AUTOSAR XML (schema 4-2-2)
package /STELLANTIS/EPT/ASWCs
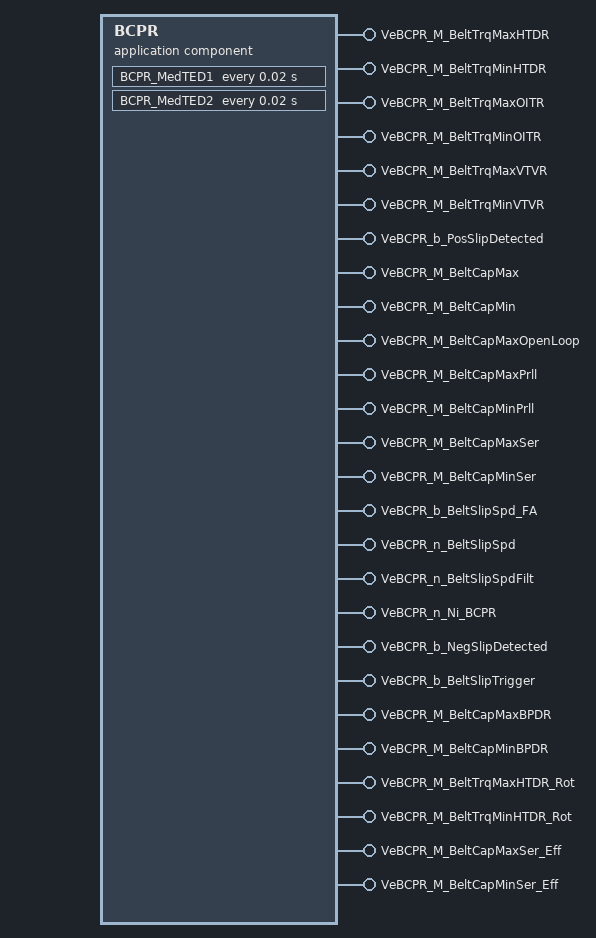
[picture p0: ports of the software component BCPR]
  application sw component type BCPR
    26 x provide port, all with nonqueued-sender-com-spec{data-element=Value, init-value=0}:
      VeBCPR_M_BeltTrqMaxHTDR: provided-interface=VeBCPR_M_BeltTrqMaxHTDR
      VeBCPR_M_BeltTrqMinHTDR: provided-interface=VeBCPR_M_BeltTrqMinHTDR
      VeBCPR_M_BeltTrqMaxOITR: provided-interface=VeBCPR_M_BeltTrqMaxOITR
      VeBCPR_M_BeltTrqMinOITR: provided-interface=VeBCPR_M_BeltTrqMinOITR
      VeBCPR_M_BeltTrqMaxVTVR: provided-interface=VeBCPR_M_BeltTrqMaxVTVR
      VeBCPR_M_BeltTrqMinVTVR: provided-interface=VeBCPR_M_BeltTrqMinVTVR
      VeBCPR_b_PosSlipDetected: provided-interface=VeBCPR_b_PosSlipDetected
      VeBCPR_M_BeltCapMax: provided-interface=VeBCPR_M_BeltCapMax
      VeBCPR_M_BeltCapMin: provided-interface=VeBCPR_M_BeltCapMin
      VeBCPR_M_BeltCapMaxOpenLoop: provided-interface=VeBCPR_M_BeltCapMaxOpenLoop
      VeBCPR_M_BeltCapMaxPrll: provided-interface=VeBCPR_M_BeltCapMaxPrll
      VeBCPR_M_BeltCapMinPrll: provided-interface=VeBCPR_M_BeltCapMinPrll
      VeBCPR_M_BeltCapMaxSer: provided-interface=VeBCPR_M_BeltCapMaxSer
      VeBCPR_M_BeltCapMinSer: provided-interface=VeBCPR_M_BeltCapMinSer
      VeBCPR_b_BeltSlipSpd_FA: provided-interface=VeBCPR_b_BeltSlipSpd_FA
      VeBCPR_n_BeltSlipSpd: provided-interface=VeBCPR_n_BeltSlipSpd
      VeBCPR_n_BeltSlipSpdFilt: provided-interface=VeBCPR_n_BeltSlipSpdFilt
      VeBCPR_n_Ni_BCPR: provided-interface=VeBCPR_n_Ni_BCPR
      VeBCPR_b_NegSlipDetected: provided-interface=VeBCPR_b_NegSlipDetected
      VeBCPR_b_BeltSlipTrigger: provided-interface=VeBCPR_b_BeltSlipTrigger
      VeBCPR_M_BeltCapMaxBPDR: provided-interface=VeBCPR_M_BeltCapMaxBPDR
      VeBCPR_M_BeltCapMinBPDR: provided-interface=VeBCPR_M_BeltCapMinBPDR
      VeBCPR_M_BeltTrqMaxHTDR_Rot: provided-interface=VeBCPR_M_BeltTrqMaxHTDR_Rot
      VeBCPR_M_BeltTrqMinHTDR_Rot: provided-interface=VeBCPR_M_BeltTrqMinHTDR_Rot
      VeBCPR_M_BeltCapMaxSer_Eff: provided-interface=VeBCPR_M_BeltCapMaxSer_Eff
      VeBCPR_M_BeltCapMinSer_Eff: provided-interface=VeBCPR_M_BeltCapMinSer_Eff
    behavior IB_BCPR: data-type-mapping=msADTtoIDTMapping, handle-termination-and-restart=NO-SUPPORT
      timing event Event_MedTED1: start-on-event=BCPR_MedTED1, period=0.02
      timing event Event_MedTED2: start-on-event=BCPR_MedTED2, period=0.02
      init event Event_BCPR_ac_Init: start-on-event=BCPR_ac_Init
      init event Event_PwrOn: start-on-event=BCPR_PwrOn
      explicit-inter-runnable-variables:
        12 x data, all with category=VALUE, sw-calibration-access=READ-ONLY, init-value=0:
          VeBCPC_M_BeltCapMaxOpenLoopTact_write_IRV: type=Float
          VeBCPC_M_BeltCapMinOpenLoopTact_write_IRV: type=Float
          VeBCPC_M_BeltCapMaxOpenLoopPrll_write_IRV: type=Float
          VeBCPC_M_BeltCapMinOpenLoopPrll_write_IRV: type=Float
          VeBCPC_M_BeltCapMaxOpenLoopSer_write_IRV: type=Float
          VeBCPC_M_BeltCapMinOpenLoopSer_write_IRV: type=Float
          VeBCPC_M_BeltCapMaxOpenLoopPred_write_IRV: type=Float
          VeBCPC_M_BeltCapMinOpenLoopPred_write_IRV: type=Float
          PrllRngEqn_write_IRV: type=Boolean
          PrllPreLeadState_write_IRV: type=Boolean
          VeBCPR_n_BeltSlipSpd_write_IRV: type=Float
          VeBCPR_n_BeltSlipSpdFilt_write_IRV: type=Float
      4 x runnable:
        BCPR_ac_Init
        BCPR_PwrOn
          data-send-points:
            26 x access:
              OUT_VeBCPR_M_BeltTrqMaxHTDR_Rot_Value: accessed-variable=VeBCPR_M_BeltTrqMaxHTDR_Rot.Value
              OUT_VeBCPR_M_BeltCapMaxOpenLoop_Value: accessed-variable=VeBCPR_M_BeltCapMaxOpenLoop.Value
              OUT_VeBCPR_M_BeltCapMaxPrll_Value: accessed-variable=VeBCPR_M_BeltCapMaxPrll.Value
              OUT_VeBCPR_M_BeltCapMinPrll_Value: accessed-variable=VeBCPR_M_BeltCapMinPrll.Value
              OUT_VeBCPR_M_BeltCapMaxSer_Value: accessed-variable=VeBCPR_M_BeltCapMaxSer.Value
              OUT_VeBCPR_M_BeltCapMinSer_Value: accessed-variable=VeBCPR_M_BeltCapMinSer.Value
              OUT_VeBCPR_n_BeltSlipSpd_Value: accessed-variable=VeBCPR_n_BeltSlipSpd.Value
              OUT_VeBCPR_n_BeltSlipSpdFilt_Value: accessed-variable=VeBCPR_n_BeltSlipSpdFilt.Value
              OUT_VeBCPR_n_Ni_BCPR_Value: accessed-variable=VeBCPR_n_Ni_BCPR.Value
              OUT_VeBCPR_M_BeltCapMaxBPDR_Value: accessed-variable=VeBCPR_M_BeltCapMaxBPDR.Value
              OUT_VeBCPR_M_BeltCapMinBPDR_Value: accessed-variable=VeBCPR_M_BeltCapMinBPDR.Value
              OUT_VeBCPR_M_BeltTrqMaxHTDR_Value: accessed-variable=VeBCPR_M_BeltTrqMaxHTDR.Value
              OUT_VeBCPR_b_PosSlipDetected_Value: accessed-variable=VeBCPR_b_PosSlipDetected.Value
              OUT_VeBCPR_b_BeltSlipSpd_FA_Value: accessed-variable=VeBCPR_b_BeltSlipSpd_FA.Value
              OUT_VeBCPR_b_NegSlipDetected_Value: accessed-variable=VeBCPR_b_NegSlipDetected.Value
              OUT_VeBCPR_b_BeltSlipTrigger_Value: accessed-variable=VeBCPR_b_BeltSlipTrigger.Value
              OUT_VeBCPR_M_BeltTrqMinHTDR_Rot_Value: accessed-variable=VeBCPR_M_BeltTrqMinHTDR_Rot.Value
              OUT_VeBCPR_M_BeltCapMaxSer_Eff_Value: accessed-variable=VeBCPR_M_BeltCapMaxSer_Eff.Value
              OUT_VeBCPR_M_BeltCapMinSer_Eff_Value: accessed-variable=VeBCPR_M_BeltCapMinSer_Eff.Value
              OUT_VeBCPR_M_BeltTrqMinHTDR_Value: accessed-variable=VeBCPR_M_BeltTrqMinHTDR.Value
              OUT_VeBCPR_M_BeltTrqMaxOITR_Value: accessed-variable=VeBCPR_M_BeltTrqMaxOITR.Value
              OUT_VeBCPR_M_BeltTrqMinOITR_Value: accessed-variable=VeBCPR_M_BeltTrqMinOITR.Value
              OUT_VeBCPR_M_BeltTrqMaxVTVR_Value: accessed-variable=VeBCPR_M_BeltTrqMaxVTVR.Value
              OUT_VeBCPR_M_BeltTrqMinVTVR_Value: accessed-variable=VeBCPR_M_BeltTrqMinVTVR.Value
              OUT_VeBCPR_M_BeltCapMax_Value: accessed-variable=VeBCPR_M_BeltCapMax.Value
              OUT_VeBCPR_M_BeltCapMin_Value: accessed-variable=VeBCPR_M_BeltCapMin.Value
          written-local-variables:
            12 x access:
              WV_PrllPreLeadState_write_IRV: accessed-variable=PrllPreLeadState_write_IRV
              WV_PrllRngEqn_write_IRV: accessed-variable=PrllRngEqn_write_IRV
              WV_VeBCPC_M_BeltCapMaxOpenLoopPred_write_IRV: accessed-variable=VeBCPC_M_BeltCapMaxOpenLoopPred_write_IRV
              WV_VeBCPC_M_BeltCapMaxOpenLoopPrll_write_IRV: accessed-variable=VeBCPC_M_BeltCapMaxOpenLoopPrll_write_IRV
              WV_VeBCPC_M_BeltCapMaxOpenLoopSer_write_IRV: accessed-variable=VeBCPC_M_BeltCapMaxOpenLoopSer_write_IRV
              WV_VeBCPC_M_BeltCapMaxOpenLoopTact_write_IRV: accessed-variable=VeBCPC_M_BeltCapMaxOpenLoopTact_write_IRV
              WV_VeBCPC_M_BeltCapMinOpenLoopPred_write_IRV: accessed-variable=VeBCPC_M_BeltCapMinOpenLoopPred_write_IRV
              WV_VeBCPC_M_BeltCapMinOpenLoopPrll_write_IRV: accessed-variable=VeBCPC_M_BeltCapMinOpenLoopPrll_write_IRV
              WV_VeBCPC_M_BeltCapMinOpenLoopSer_write_IRV: accessed-variable=VeBCPC_M_BeltCapMinOpenLoopSer_write_IRV
              WV_VeBCPC_M_BeltCapMinOpenLoopTact_write_IRV: accessed-variable=VeBCPC_M_BeltCapMinOpenLoopTact_write_IRV
              WV_VeBCPR_n_BeltSlipSpdFilt_write_IRV: accessed-variable=VeBCPR_n_BeltSlipSpdFilt_write_IRV
              WV_VeBCPR_n_BeltSlipSpd_write_IRV: accessed-variable=VeBCPR_n_BeltSlipSpd_write_IRV
        BCPR_MedTED1
          data-send-points:
            6 x access:
              OUT_VeBCPR_M_BeltCapMaxOpenLoop_Value: accessed-variable=VeBCPR_M_BeltCapMaxOpenLoop.Value
              OUT_VeBCPR_n_BeltSlipSpd_Value: accessed-variable=VeBCPR_n_BeltSlipSpd.Value
              OUT_VeBCPR_n_BeltSlipSpdFilt_Value: accessed-variable=VeBCPR_n_BeltSlipSpdFilt.Value
              OUT_VeBCPR_n_Ni_BCPR_Value: accessed-variable=VeBCPR_n_Ni_BCPR.Value
              OUT_VeBCPR_b_BeltSlipSpd_FA_Value: accessed-variable=VeBCPR_b_BeltSlipSpd_FA.Value
              OUT_VeBCPR_b_BeltSlipTrigger_Value: accessed-variable=VeBCPR_b_BeltSlipTrigger.Value
        BCPR_MedTED2
          data-send-points:
            20 x access:
              OUT_VeBCPR_M_BeltTrqMaxHTDR_Rot_Value: accessed-variable=VeBCPR_M_BeltTrqMaxHTDR_Rot.Value
              OUT_VeBCPR_M_BeltCapMaxPrll_Value: accessed-variable=VeBCPR_M_BeltCapMaxPrll.Value
              OUT_VeBCPR_M_BeltCapMinPrll_Value: accessed-variable=VeBCPR_M_BeltCapMinPrll.Value
              OUT_VeBCPR_M_BeltCapMaxSer_Value: accessed-variable=VeBCPR_M_BeltCapMaxSer.Value
              OUT_VeBCPR_M_BeltCapMinSer_Value: accessed-variable=VeBCPR_M_BeltCapMinSer.Value
              OUT_VeBCPR_M_BeltCapMaxBPDR_Value: accessed-variable=VeBCPR_M_BeltCapMaxBPDR.Value
              OUT_VeBCPR_M_BeltCapMinBPDR_Value: accessed-variable=VeBCPR_M_BeltCapMinBPDR.Value
              OUT_VeBCPR_M_BeltTrqMaxHTDR_Value: accessed-variable=VeBCPR_M_BeltTrqMaxHTDR.Value
              OUT_VeBCPR_b_PosSlipDetected_Value: accessed-variable=VeBCPR_b_PosSlipDetected.Value
              OUT_VeBCPR_b_NegSlipDetected_Value: accessed-variable=VeBCPR_b_NegSlipDetected.Value
              OUT_VeBCPR_M_BeltTrqMinHTDR_Rot_Value: accessed-variable=VeBCPR_M_BeltTrqMinHTDR_Rot.Value
              OUT_VeBCPR_M_BeltCapMaxSer_Eff_Value: accessed-variable=VeBCPR_M_BeltCapMaxSer_Eff.Value
              OUT_VeBCPR_M_BeltCapMinSer_Eff_Value: accessed-variable=VeBCPR_M_BeltCapMinSer_Eff.Value
              OUT_VeBCPR_M_BeltTrqMinHTDR_Value: accessed-variable=VeBCPR_M_BeltTrqMinHTDR.Value
              OUT_VeBCPR_M_BeltTrqMaxOITR_Value: accessed-variable=VeBCPR_M_BeltTrqMaxOITR.Value
              OUT_VeBCPR_M_BeltTrqMinOITR_Value: accessed-variable=VeBCPR_M_BeltTrqMinOITR.Value
              OUT_VeBCPR_M_BeltTrqMaxVTVR_Value: accessed-variable=VeBCPR_M_BeltTrqMaxVTVR.Value
              OUT_VeBCPR_M_BeltTrqMinVTVR_Value: accessed-variable=VeBCPR_M_BeltTrqMinVTVR.Value
              OUT_VeBCPR_M_BeltCapMax_Value: accessed-variable=VeBCPR_M_BeltCapMax.Value
              OUT_VeBCPR_M_BeltCapMin_Value: accessed-variable=VeBCPR_M_BeltCapMin.Value
      variation point proxy Variant_BCPR_1: category=CONDITION, condition-access=0
      variation point proxy Variant_HSCL_FEAD1: category=CONDITION, condition-access=0
